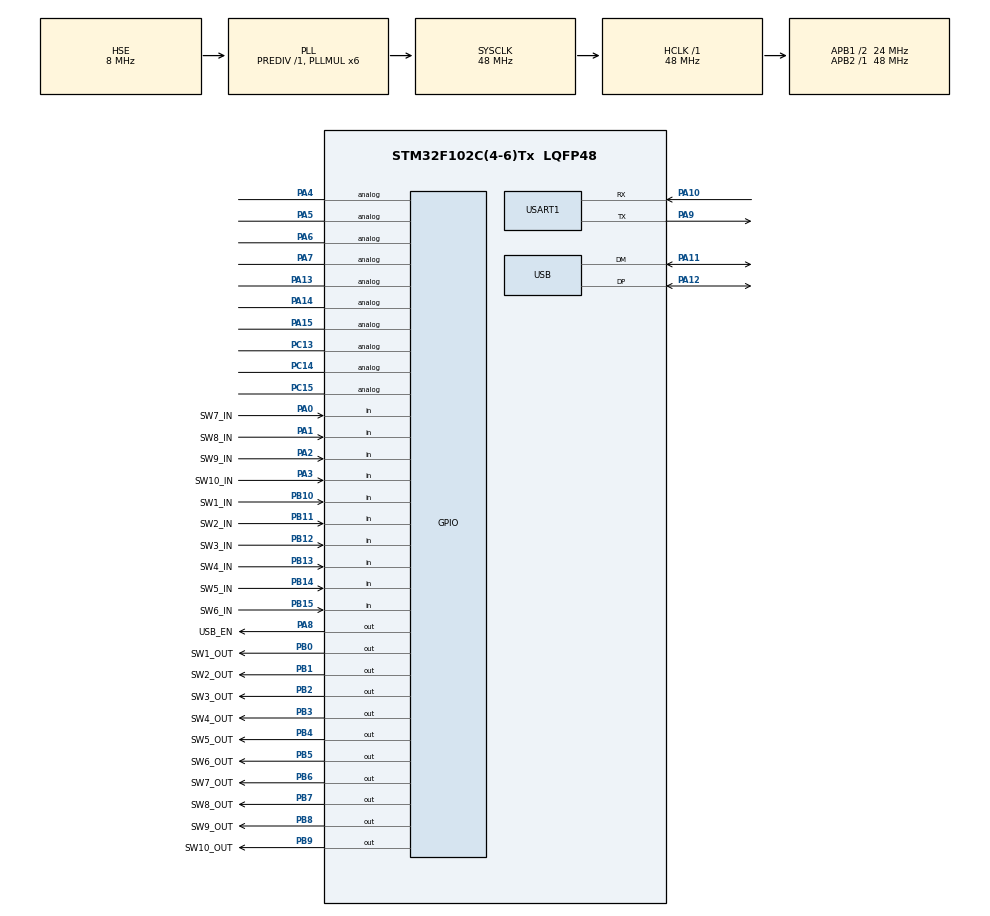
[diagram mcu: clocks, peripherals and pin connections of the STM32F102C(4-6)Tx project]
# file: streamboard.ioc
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Mcu.Family=STM32F1
Mcu.Name=STM32F102C(4-6)Tx
Mcu.Package=LQFP48
NVIC.PriorityGroup=NVIC_PRIORITYGROUP_4
NVIC.USB_LP_IRQn=true\:0\:0\:false\:false\:true\:true\:true
PA0-WKUP.GPIO_Label=SW7_IN
PA0-WKUP.GPIO_PuPd=GPIO_PULLUP
PA0-WKUP.Signal=GPIO_Input
PA1.GPIO_Label=SW8_IN
PA1.GPIO_PuPd=GPIO_PULLUP
PA1.Signal=GPIO_Input
PA10.Mode=Asynchronous
PA10.Signal=USART1_RX
PA11.Mode=Device
PA11.Signal=USB_DM
PA12.Mode=Device
PA12.Signal=USB_DP
PA13.Signal=GPIO_Analog
PA14.Signal=GPIO_Analog
PA15.Signal=GPIO_Analog
PA2.GPIO_Label=SW9_IN
PA2.GPIO_PuPd=GPIO_PULLUP
PA2.Signal=GPIO_Input
PA3.GPIO_Label=SW10_IN
PA3.GPIO_PuPd=GPIO_PULLUP
PA3.Signal=GPIO_Input
PA4.Signal=GPIO_Analog
PA5.Signal=GPIO_Analog
PA6.Signal=GPIO_Analog
PA7.Signal=GPIO_Analog
PA8.GPIO_Label=USB_EN
PA8.Signal=GPIO_Output
PA9.Mode=Asynchronous
PA9.Signal=USART1_TX
PB0.GPIO_Label=SW1_OUT
PB0.Signal=GPIO_Output
PB1.GPIO_Label=SW2_OUT
PB1.Signal=GPIO_Output
PB10.GPIO_Label=SW1_IN
PB10.GPIO_PuPd=GPIO_PULLUP
PB10.Signal=GPIO_Input
PB11.GPIO_Label=SW2_IN
PB11.GPIO_PuPd=GPIO_PULLUP
PB11.Signal=GPIO_Input
PB12.GPIO_Label=SW3_IN
PB12.GPIO_PuPd=GPIO_PULLUP
PB12.Signal=GPIO_Input
PB13.GPIO_Label=SW4_IN
PB13.GPIO_PuPd=GPIO_PULLUP
PB13.Signal=GPIO_Input
PB14.GPIO_Label=SW5_IN
PB14.GPIO_PuPd=GPIO_PULLUP
PB14.Signal=GPIO_Input
PB15.GPIO_Label=SW6_IN
PB15.GPIO_PuPd=GPIO_PULLUP
PB15.Signal=GPIO_Input
PB2.GPIO_Label=SW3_OUT
PB2.Signal=GPIO_Output
PB3.GPIO_Label=SW4_OUT
PB3.Signal=GPIO_Output
PB4.GPIO_Label=SW5_OUT
PB4.Signal=GPIO_Output
PB5.GPIO_Label=SW6_OUT
PB5.Signal=GPIO_Output
PB6.GPIO_Label=SW7_OUT
PB6.Signal=GPIO_Output
PB7.GPIO_Label=SW8_OUT
PB7.Signal=GPIO_Output
PB8.GPIO_Label=SW9_OUT
PB8.Signal=GPIO_Output
PB9.GPIO_Label=SW10_OUT
PB9.Signal=GPIO_Output
PC13-TAMPER-RTC.Signal=GPIO_Analog
PC14-OSC32_IN.Signal=GPIO_Analog
PC15-OSC32_OUT.Signal=GPIO_Analog
PD0-OSC_IN.Mode=HSE-External-Oscillator
PD0-OSC_IN.Signal=RCC_OSC_IN
PD1-OSC_OUT.Mode=HSE-External-Oscillator
PD1-OSC_OUT.Signal=RCC_OSC_OUT
ProjectManager.HeapSize=0x200
ProjectManager.StackSize=0x400
ProjectManager.TargetToolchain=STM32CubeIDE
RCC.AHBFreq_Value=48000000
RCC.APB1CLKDivider=RCC_HCLK_DIV2
RCC.APB1Freq_Value=24000000
RCC.APB1TimFreq_Value=48000000
RCC.APB2Freq_Value=48000000
RCC.HCLKFreq_Value=48000000
RCC.PLLMUL=RCC_PLL_MUL6
RCC.PLLSourceVirtual=RCC_PLLSOURCE_HSE
RCC.SYSCLKFreq_VALUE=48000000
RCC.SYSCLKSource=RCC_SYSCLKSOURCE_PLLCLK
RCC.USBFreq_Value=48000000
TIM2.Channel-PWM\ Generation1\ No\ Output=TIM_CHANNEL_1
USART1.VirtualMode=VM_ASYNC
USB_DEVICE.APP_RX_DATA_SIZE=128
USB_DEVICE.APP_TX_DATA_SIZE=128
USB_DEVICE.CLASS_NAME_FS=CDC
USB_DEVICE.VirtualMode=Cdc
USB_DEVICE.VirtualModeFS=Cdc_FS
VP_SYS_VS_ND.Mode=No_Debug
VP_TIM2_VS_ClockSourceINT.Mode=Internal
VP_TIM2_VS_ClockSourceITR.Mode=TriggerSource_ITR0
VP_TIM2_VS_ControllerModeGated.Mode=Gated Mode
VP_TIM2_VS_no_output1.Mode=PWM Generation1 No Output
VP_USB_DEVICE_VS_USB_DEVICE_CDC_FS.Mode=CDC_FS
board=custom

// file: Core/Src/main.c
/* USER CODE BEGIN Header */
/**
  ******************************************************************************
  * @file           : main.c
  * @brief          : Main program body
  ******************************************************************************
  * @attention
  *
  * <h2><center>&copy; Copyright (c) 2020 STMicroelectronics.
  * All rights reserved.</center></h2>
  *
  * This software component is licensed by ST under BSD 3-Clause license,
  * the "License"; You may not use this file except in compliance with the
  * License. You may obtain a copy of the License at:
  *                        opensource.org/licenses/BSD-3-Clause
  *
  ******************************************************************************
  */
/* USER CODE END Header */

#include "main.h"
#include "tim.h"
#include "usart.h"
#include "usb_device.h"
#include "gpio.h"

/* USER CODE BEGIN Includes */
#include "user_interface.h"
/* USER CODE END Includes */

void SystemClock_Config(void);

int main(void)
{
  /* USER CODE BEGIN 1 */
  uint8_t led_toggle_state = 0;
  /* USER CODE END 1 */

  /* MCU Configuration--------------------------------------------------------*/

  /* Reset of all peripherals, Initializes the Flash interface and the Systick. */
  HAL_Init();

  /* Configure the system clock */
  SystemClock_Config();

  /* Initialize all configured peripherals */
  MX_GPIO_Init();
  MX_USART1_UART_Init();
  MX_TIM2_Init();
  MX_USB_DEVICE_Init();
  /* USER CODE BEGIN 2 */

  ui_all_buttons_light_on();

  /* USER CODE END 2 */

  /* Infinite loop */
  while (1)
  {

    /* USER CODE BEGIN 3 */
//		if (led_toggle_state == 0)
//		{
//			led_toggle_state = 1;
//			ui_all_buttons_light_on();
//		}
//		else
//		{
//			led_toggle_state = 0;
//			ui_all_buttons_light_off();
//		}
		HAL_Delay(500);
  }
  /* USER CODE END 3 */
}

void SystemClock_Config(void)
{
  RCC_OscInitTypeDef RCC_OscInitStruct = {0};
  RCC_ClkInitTypeDef RCC_ClkInitStruct = {0};
  RCC_PeriphCLKInitTypeDef PeriphClkInit = {0};

  /** Initializes the CPU, AHB and APB busses clocks
  */
  RCC_OscInitStruct.OscillatorType = RCC_OSCILLATORTYPE_HSE;
  RCC_OscInitStruct.HSEState = RCC_HSE_ON;
  RCC_OscInitStruct.HSEPredivValue = RCC_HSE_PREDIV_DIV1;
  RCC_OscInitStruct.HSIState = RCC_HSI_ON;
  RCC_OscInitStruct.PLL.PLLState = RCC_PLL_ON;
  RCC_OscInitStruct.PLL.PLLSource = RCC_PLLSOURCE_HSE;
  RCC_OscInitStruct.PLL.PLLMUL = RCC_PLL_MUL6;
  if (HAL_RCC_OscConfig(&RCC_OscInitStruct) != HAL_OK)
  {
    Error_Handler();
  }
  /** Initializes the CPU, AHB and APB busses clocks
  */
  RCC_ClkInitStruct.ClockType = RCC_CLOCKTYPE_HCLK|RCC_CLOCKTYPE_SYSCLK
                              |RCC_CLOCKTYPE_PCLK1|RCC_CLOCKTYPE_PCLK2;
  RCC_ClkInitStruct.SYSCLKSource = RCC_SYSCLKSOURCE_PLLCLK;
  RCC_ClkInitStruct.AHBCLKDivider = RCC_SYSCLK_DIV1;
  RCC_ClkInitStruct.APB1CLKDivider = RCC_HCLK_DIV2;
  RCC_ClkInitStruct.APB2CLKDivider = RCC_HCLK_DIV1;

  if (HAL_RCC_ClockConfig(&RCC_ClkInitStruct, FLASH_LATENCY_1) != HAL_OK)
  {
    Error_Handler();
  }
  PeriphClkInit.PeriphClockSelection = RCC_PERIPHCLK_USB;
  PeriphClkInit.UsbClockSelection = RCC_USBCLKSOURCE_PLL;
  if (HAL_RCCEx_PeriphCLKConfig(&PeriphClkInit) != HAL_OK)
  {
    Error_Handler();
  }
}

void Error_Handler(void)
{
}

/************************ (C) COPYRIGHT STMicroelectronics *****END OF FILE****/
